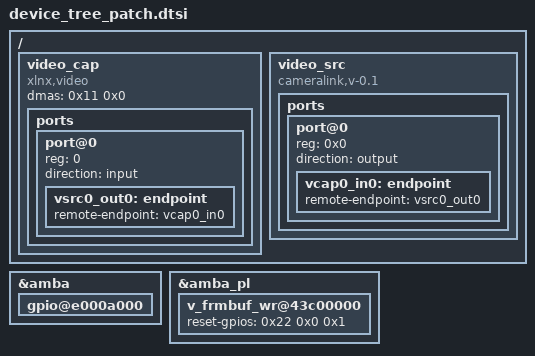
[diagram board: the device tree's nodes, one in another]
/include/ "system-conf.dtsi"

/ {
	/*video_cap_1 {
		compatible = "xlnx,video";
		dmas = <&axi_vdma_1 0>;
		dma-names = "port0";
		xlnx,video-format = <0xc>;
		xlnx,video-width = <0x8>;
		xlnx,cfa-pattern = "mono";
  
		ports {
       		      #address-cells = <1>;
                      #size-cells = <0>;
  
       			port@0 {
      			      reg = <0>;
         		      direction = "input";
                   		
				endpoint {
        				remote-endpoint = <0x17>;
                                        linux,phandle = <0x18>;
                                        phandle = <0x18>;
				};
        		};

		};
	};

	video_src_1 {
		compatible = "cameralink,v-0.1";

		ports {
			#address-cells = <0x1>;
			#size-cells = <0x0>;

			port@0 {
				reg = <0x0>;
				direction = "output";
				 endpoint {
                                        remote-endpoint = <0x18>;
                                        linux,phandle = <0x17>;
                                        phandle = <0x17>;
                                };

			};
		};
	};
	*/
	video_cap {
		compatible = "xlnx,video"; // xilinx driver.xilinx-vipp.c
		dma-names = "port0";
		dmas = <0x11 0x0>; //connect the framebuffer node
                //following 3 line are not nedded
		//xlnx,video-format = <0xc>;  
		//xlnx,video-width = <0x8>;
		//xlnx,cfa-pattern = "mono";
  		
		ports {
       		      #address-cells = <1>;
                      #size-cells = <0>;
  
       			port@0 {
      			      reg = <0>;
         		      direction = "input";
                   		//connect to video src	
				vsrc0_out0: endpoint {
        	                                remote-endpoint = <&vcap0_in0>;        
        			};
        		};

		};
	};

	video_src {
		compatible = "cameralink,v-0.1"; //connect to driver

		ports {
			#address-cells = <0x1>;
			#size-cells = <0x0>;

			port@0 {
				reg = <0x0>;
				direction = "output";
				//connect to video cap
				vcap0_in0: endpoint {
                                        remote-endpoint = <&vsrc0_out0>;
                                };

			};
		};
	};
};

&amba{
	gpio@e000a000 {
			linux,phandle = <0x22>;//connect to framebuffer
			phandle = <0x22>;//connect to framebuffer 
		};	
};
&amba_pl{
	
	/*interrupt-controller@41800000 {
		interrupt-parent = <0x4>;
		//interrupts = <0x0 0x1d 0x4>;  
		interrupts = <0x0 0x1d 0x1>;//this is try to make edge trigger for our need  
		//compatible = "xps-intc-1.00.a";
	};*/

	v_frmbuf_wr@43c00000 {
                reset-gpios = <0x22 0x0 0x1>; //connect to zynq gpio,needed for driver code because it is hardcoded in the driver
		linux,phandle= <0x11>;        //to coneect the video src
		phandle = <0x11>;
		//interrupts = <0x0 0x1e 0x1>;
	};
	//no need to add the full node as below.just additional lines are required as above.
	/*v_frmbuf_wr@43c00000 {
		#dma-cells = <0x1>;
		clock-names = "ap_clk";
		clocks = <0x1 0xf>;
		compatible = "xlnx,v-frmbuf-wr-2.1", "xlnx,axi-frmbuf-wr-v2.1";
		interrupt-names = "interrupt";
		interrupt-parent = <0x4>;
		//interrupts = <0x0 0x1d 0x1>;//this is try to make edge trigger for our need  
		//interrupts = <0x0 0x1d 0x4>;//this is level tirgger,which it is originally
		reg = <0x43c00000 0x10000>;
                reset-gpios = <0x22 0x0 0x1>; //connect to zynq gpio,needed for driver code because it is hardcoded in the driver
		xlnx,dma-addr-width = <0x20>;
		xlnx,dma-align = <0x8>;
		xlnx,max-height = <0x1000>;
		xlnx,max-width = <0x1000>;
		xlnx,pixels-per-clock = <0x1>;
		xlnx,s-axi-ctrl-addr-width = <0x7>;
		xlnx,s-axi-ctrl-data-width = <0x20>;
		xlnx,vid-formats = "bgr888";
		xlnx,video-width = <0x8>;
		//linux,phandle= <0x11>;
		phandle = <0x11>;
	};*/
};
